# ipro6s register map
Vendor: intelpro; Series: IPRO6S
ipro6s register description
CPU: ipro6s, little endian
Registers are 32-bit, read-write, reset 0x0 unless marked. A register's access mark holds for its fields unless they carry their own. Offsets are from the block's base; lines under a group give offsets from that group; [hi:lo] are bit positions; {n}, {i} and the like mark numbered series; 'fields as' and 'values as' point back to an identical list; <NAME> marks a mode.

## Memory map
0x30000000 GLB size 0x1000
0x30001000 RF size 0x1000
0x30001000 RF_WLP1 size 0x1000
0x30001000 RF_FSM size 0x1000
0x30001000 RF_EPA size 0x1000
0x30002000 GPIP size 0x1000
0x30003000 BZ_PHY size 0x1000
0x30004000 BZ_PHY_AGC size 0x1000
0x30005000 SEC_DBG size 0x1000
0x30006000 TZC_SEC size 0x1000
0x30007000 TZC_NSEC size 0x1000
0x30008000 CCI size 0x1000
0x30009000 MCU_MISC size 0x1000
0x3000A000 UART0 size 0x1000
0x3000B000 UART1 size 0x1000
0x3000C000 EF_CTRL size 0x1000
0x3000C000 EF_DATA_0 size 0x1000
0x3000C000 EF_DATA_1 size 0x1000
0x3000D000 SPI size 0x1000
0x3000E000 I2C0 size 0x1000
0x3000F000 I2C1 size 0x1000
0x30010000 PWM size 0x1000
0x30011000 LTMR size 0x1000
0x30012000 CKS size 0x1000
0x30013000 I2S size 0x1000
0x30016000 DBI size 0x1000
0x30017000 MM_MISC size 0x1000
0x30018000 D2XA size 0x1000
0x30019000 D2XB size 0x1000
0x3001A000 MJCOMB_CSR size 0x1000
0x3001A000 MJENC_Q_SRAM size 0x1000
0x30054000 RF2 size 0x1000
0x30080000 SEC_ENG size 0x1000
0x30081000 DMA size 0x1000
0x30082000 SF_CTRL size 0x1000
0x30083000 ETHMAC size 0x1000
0x3008E000 PDS size 0x1000
0x3008F000 HBN size 0x1000
0x3008F000 AON size 0x1000

## RF_WLP1
Base 0x30001000
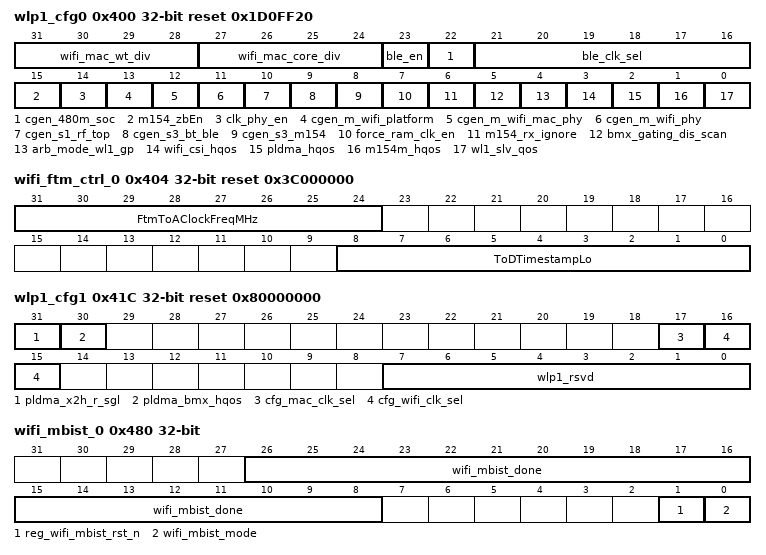
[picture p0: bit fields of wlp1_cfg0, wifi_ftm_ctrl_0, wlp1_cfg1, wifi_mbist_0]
0x400 wlp1_cfg0 reset 0x1D0FF20
  [31:28] wifi_mac_wt_div, [27:24] wifi_mac_core_div, [23] ble_en, [22] cgen_480m_soc, [21:16] ble_clk_sel, [15] m154_zbEn, [14] clk_phy_en, [13] cgen_m_wifi_platform, [12] cgen_m_wifi_mac_phy, [11] cgen_m_wifi_phy, [10] cgen_s1_rf_top, [9] cgen_s3_bt_ble, [8] cgen_s3_m154, [7] force_ram_clk_en, [6] m154_rx_ignore, [5] bmx_gating_dis_scan, [4] arb_mode_wl1_gp, [3] wifi_csi_hqos, [2] pldma_hqos, [1] m154m_hqos, [0] wl1_slv_qos
0x404 wifi_ftm_ctrl_0 reset 0x3C000000 (reset mask 0xFF000000)
  [31:24] FtmToAClockFreqMHz, [8:0] ToDTimestampLo ro
0x408 wifi_ftm_ctrl_1 reset not defined
  [31:0] ToDTimestampHi ro
0x40C wifi_ftm_ctrl_2 reset not defined
  [8:0] FtmToATimestampLo ro
0x410 wifi_ftm_ctrl_3 reset not defined
  [31:0] FtmToATimestampHi ro
0x414 wifi_ftm_ctrl_4 reset not defined
  [8:0] ToATimestampLo ro
0x418 wifi_ftm_ctrl_5 reset not defined
  [31:0] ToATimestampHi ro
0x41C wlp1_cfg1 reset 0x80000000
  [31] pldma_x2h_r_sgl, [30] pldma_bmx_hqos, [17] cfg_mac_clk_sel, [16:15] cfg_wifi_clk_sel, [7:0] wlp1_rsvd
0x480 wifi_mbist_0 (reset mask 0x3)
  [26:8] wifi_mbist_done ro, [1] reg_wifi_mbist_rst_n, [0] wifi_mbist_mode
0x484 wifi_mbist_1 reset not defined
  [26:8] wifi_mbist_fail ro

## RF_FSM
Base 0x30001000
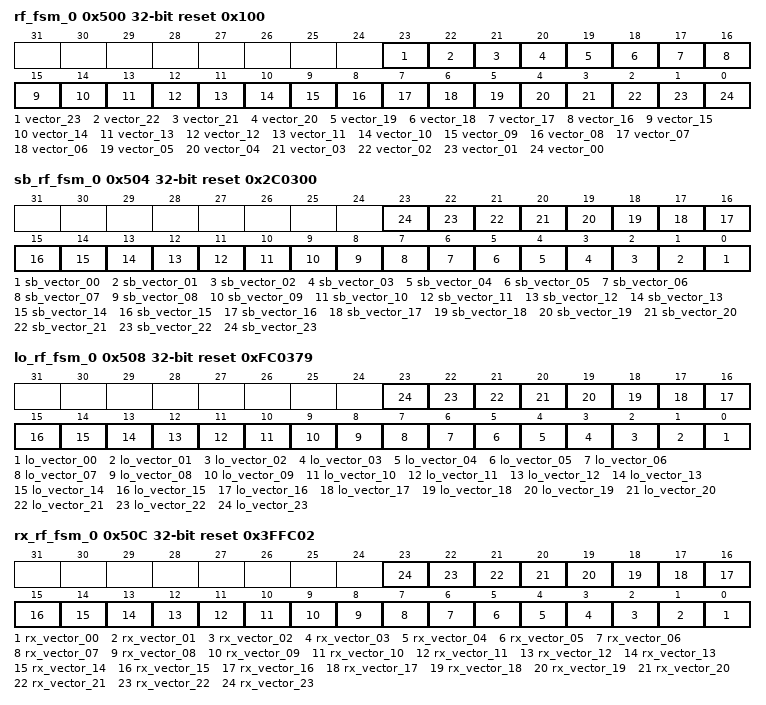
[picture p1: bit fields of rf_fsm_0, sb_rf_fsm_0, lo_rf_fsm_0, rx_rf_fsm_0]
0x500 rf_fsm_0 reset 0x100
  [23] vector_23 — pu_rcal
  [22] vector_22 — wifipll_en_div2
  [21] vector_21 — pu_vco
  [20] vector_20 — pu_vbuf_lodist
  [19] vector_19 — pu_vbuf_fbdv
  [18] vector_18 — pu_adda_ldo
  [17] vector_17 — pu_lna
  [16] vector_16 — pu_rmxgm
  [15] vector_15 — pu_rmx
  [14] vector_14 — pu_rbb
  [13] vector_13 — pu_pkdet
  [12] vector_12 — pu_adc
  [11] vector_11 — adc_clk_en
  [10] vector_10 — pu_rosdac
  [9] vector_09 — trsw_en_1
  [8] vector_08 — trsw_en_0
  [7] vector_07 — pu_pa
  [6] vector_06 — pu_tmx
  [5] vector_05 — pu_tbb
  [4] vector_04 — pu_dac
  [3] vector_03 — pu_tosdac
  [2] vector_02 — pu_pwrmx
  [1] vector_01 — pu_rxbuf
  [0] vector_00 — pu_txbuf
0x504 sb_rf_fsm_0 reset 0x2C0300
  [n] sb_vector_{n:02} (n=0..23)
0x508 lo_rf_fsm_0 reset 0xFC0379
  [n] lo_vector_{n:02} (n=0..23)
0x50C rx_rf_fsm_0 reset 0x3FFC02
  [n] rx_vector_{n:02} (n=0..23)
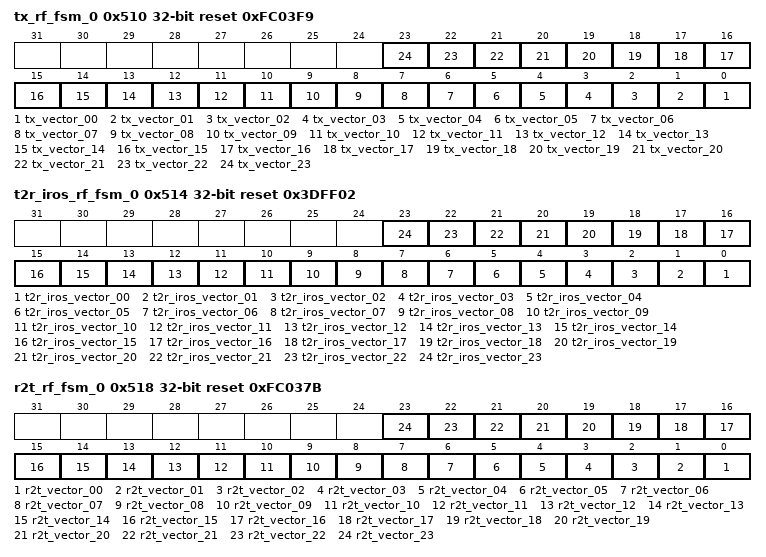
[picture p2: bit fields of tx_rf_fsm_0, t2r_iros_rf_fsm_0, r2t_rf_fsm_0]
0x510 tx_rf_fsm_0 reset 0xFC03F9
  [n] tx_vector_{n:02} (n=0..23)
0x514 t2r_iros_rf_fsm_0 reset 0x3DFF02
  [n] t2r_iros_vector_{n:02} (n=0..23)
0x518 r2t_rf_fsm_0 reset 0xFC037B
  [n] r2t_vector_{n:02} (n=0..23)
